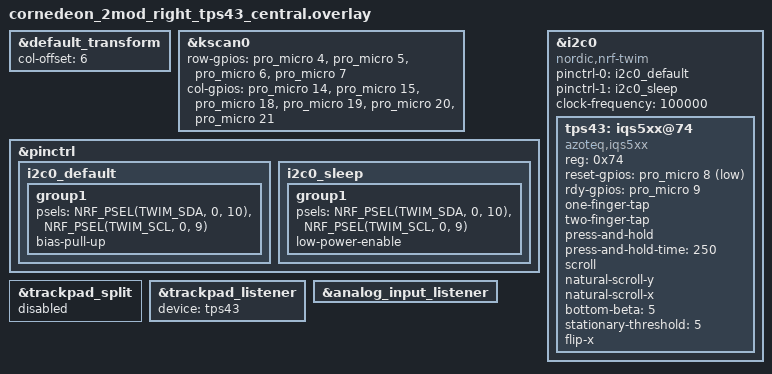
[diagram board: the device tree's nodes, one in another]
#include "cornedeon_2mod.dtsi"

&default_transform {
    col-offset = <6>;
};

&kscan0 {
    row-gpios
        = <&pro_micro 4 (GPIO_ACTIVE_HIGH | GPIO_PULL_DOWN)>
        , <&pro_micro 5 (GPIO_ACTIVE_HIGH | GPIO_PULL_DOWN)>
        , <&pro_micro 6 (GPIO_ACTIVE_HIGH | GPIO_PULL_DOWN)>
        , <&pro_micro 7 (GPIO_ACTIVE_HIGH | GPIO_PULL_DOWN)>
        ;

    col-gpios
        = <&pro_micro 14 GPIO_ACTIVE_HIGH>
        , <&pro_micro 15 GPIO_ACTIVE_HIGH>
        , <&pro_micro 18 GPIO_ACTIVE_HIGH>
        , <&pro_micro 19 GPIO_ACTIVE_HIGH>
        , <&pro_micro 20 GPIO_ACTIVE_HIGH>
        , <&pro_micro 21 GPIO_ACTIVE_HIGH>
        ;
};

&pinctrl {
	i2c0_default: i2c0_default {
		group1 {
			psels = <NRF_PSEL(TWIM_SDA, 0, 10)>,
				<NRF_PSEL(TWIM_SCL, 0, 9)>;
            bias-pull-up;
		};
	};

	i2c0_sleep: i2c0_sleep {
		group1 {
			psels = <NRF_PSEL(TWIM_SDA, 0, 10)>,
				<NRF_PSEL(TWIM_SCL, 0, 9)>;
			low-power-enable;
		};
	};
};

&i2c0 {
	compatible = "nordic,nrf-twim";
	status = "okay";

	pinctrl-0 = <&i2c0_default>;
	pinctrl-1 = <&i2c0_sleep>;
	pinctrl-names = "default", "sleep";

	clock-frequency = <100000>;

	tps43: iqs5xx@74 {
        status = "okay";
        compatible = "azoteq,iqs5xx";
        reg = <0x74>;

        reset-gpios = <&pro_micro 8 GPIO_ACTIVE_LOW>;
        rdy-gpios = <&pro_micro 9 GPIO_ACTIVE_HIGH>;

        /*
         * Potentially non-exhaustive list of configuration options.
         * See: dts/bindings/input/azoteq,iqs5xx-common.yaml for a full list.
         */
        one-finger-tap;
		two-finger-tap;
        press-and-hold;
        press-and-hold-time = <250>;

        scroll;
        natural-scroll-y;
        natural-scroll-x;

        bottom-beta = <5>;
        stationary-threshold = <5>;

        //switch-xy;
        flip-x;
    };
};

&trackpad_split {
    status = "disabled";
};

&trackpad_listener {
    status = "okay";
    device = <&tps43>;
};

&analog_input_listener {
    status = "okay";
};
